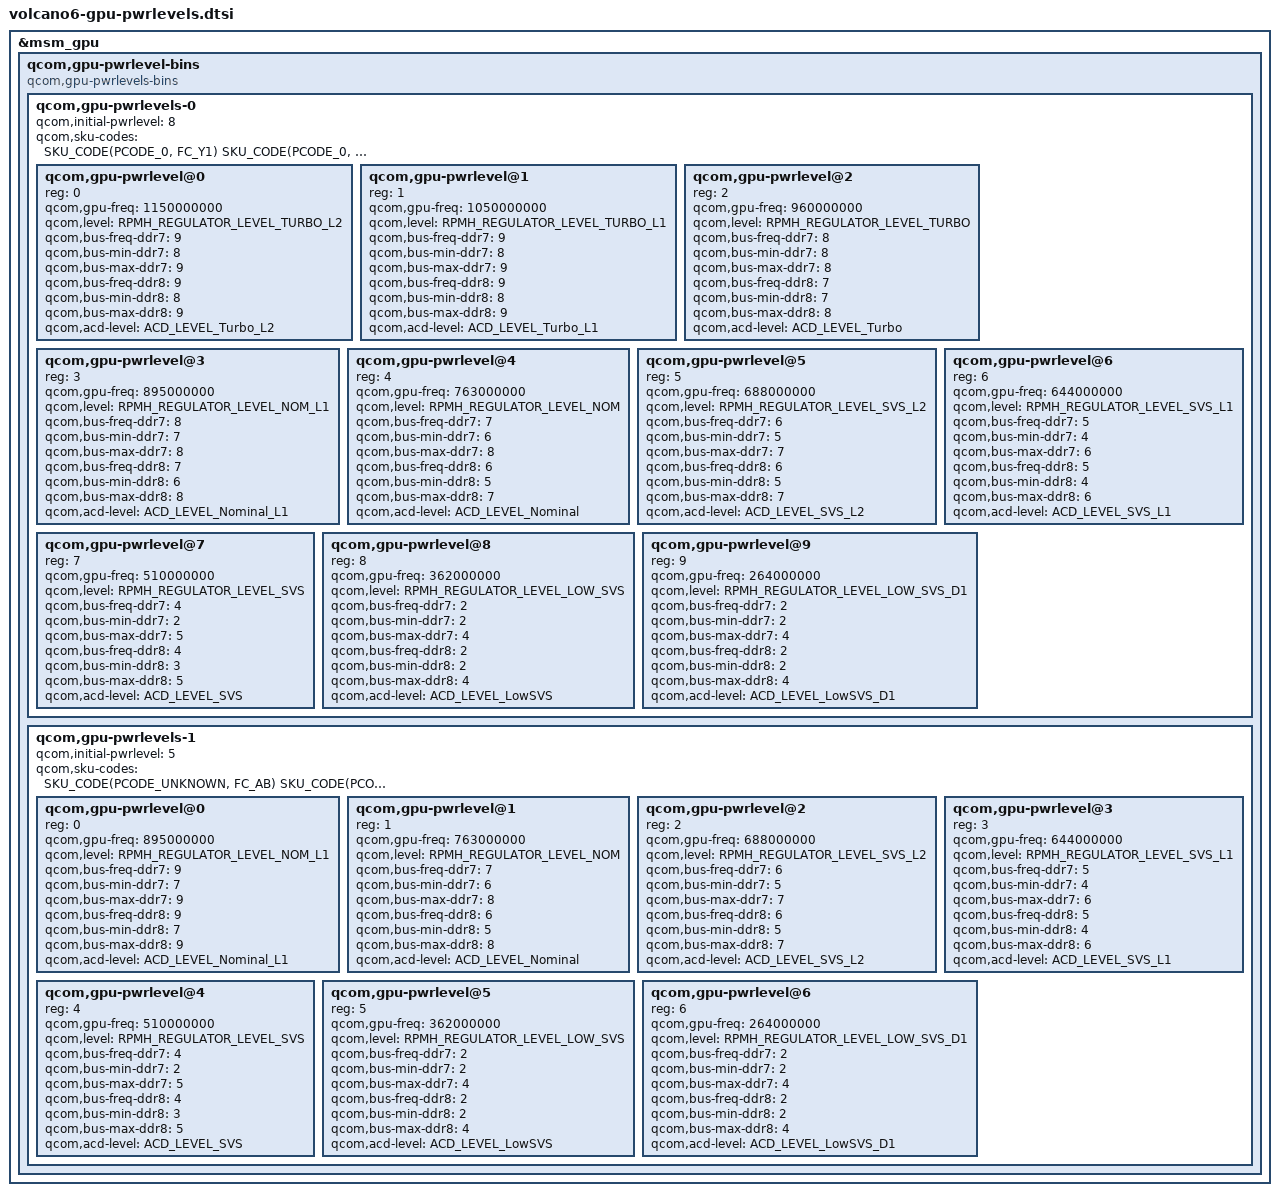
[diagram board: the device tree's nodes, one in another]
&msm_gpu {
	/* Power level bins */
	qcom,gpu-pwrlevel-bins {
		compatible = "qcom,gpu-pwrlevels-bins";

		#address-cells = <1>;
		#size-cells = <0>;

		qcom,gpu-pwrlevels-0 {

			#address-cells = <1>;
			#size-cells = <0>;

			qcom,initial-pwrlevel = <8>;

			qcom,sku-codes = <SKU_CODE(PCODE_0, FC_Y1)
				SKU_CODE(PCODE_0, FC_Y0)>;

			qcom,gpu-pwrlevel@0 {
				reg = <0>;
				qcom,gpu-freq = <1150000000>;
				qcom,level = <RPMH_REGULATOR_LEVEL_TURBO_L2>;

				qcom,bus-freq-ddr7 = <9>;
				qcom,bus-min-ddr7 = <8>;
				qcom,bus-max-ddr7 = <9>;

				qcom,bus-freq-ddr8 = <9>;
				qcom,bus-min-ddr8 = <8>;
				qcom,bus-max-ddr8 = <9>;

				qcom,acd-level = <ACD_LEVEL_Turbo_L2>;
			};

			qcom,gpu-pwrlevel@1 {
				reg = <1>;
				qcom,gpu-freq = <1050000000>;
				qcom,level = <RPMH_REGULATOR_LEVEL_TURBO_L1>;

				qcom,bus-freq-ddr7 = <9>;
				qcom,bus-min-ddr7 = <8>;
				qcom,bus-max-ddr7 = <9>;

				qcom,bus-freq-ddr8 = <9>;
				qcom,bus-min-ddr8 = <8>;
				qcom,bus-max-ddr8 = <9>;

				qcom,acd-level = <ACD_LEVEL_Turbo_L1>;
			};

			qcom,gpu-pwrlevel@2 {
				reg = <2>;
				qcom,gpu-freq = <960000000>;
				qcom,level = <RPMH_REGULATOR_LEVEL_TURBO>;

				qcom,bus-freq-ddr7 = <8>;
				qcom,bus-min-ddr7 = <8>;
				qcom,bus-max-ddr7 = <8>;

				qcom,bus-freq-ddr8 = <7>;
				qcom,bus-min-ddr8 = <7>;
				qcom,bus-max-ddr8 = <8>;

				qcom,acd-level = <ACD_LEVEL_Turbo>;
			};

			qcom,gpu-pwrlevel@3 {
				reg = <3>;
				qcom,gpu-freq = <895000000>;
				qcom,level = <RPMH_REGULATOR_LEVEL_NOM_L1>;

				qcom,bus-freq-ddr7 = <8>;
				qcom,bus-min-ddr7 = <7>;
				qcom,bus-max-ddr7 = <8>;

				qcom,bus-freq-ddr8 = <7>;
				qcom,bus-min-ddr8 = <6>;
				qcom,bus-max-ddr8 = <8>;

				qcom,acd-level = <ACD_LEVEL_Nominal_L1>;
			};

			qcom,gpu-pwrlevel@4 {
				reg = <4>;
				qcom,gpu-freq = <763000000>;
				qcom,level = <RPMH_REGULATOR_LEVEL_NOM>;

				qcom,bus-freq-ddr7 = <7>;
				qcom,bus-min-ddr7 = <6>;
				qcom,bus-max-ddr7 = <8>;

				qcom,bus-freq-ddr8 = <6>;
				qcom,bus-min-ddr8 = <5>;
				qcom,bus-max-ddr8 = <7>;

				qcom,acd-level = <ACD_LEVEL_Nominal>;
			};

			qcom,gpu-pwrlevel@5 {
				reg = <5>;
				qcom,gpu-freq = <688000000>;
				qcom,level = <RPMH_REGULATOR_LEVEL_SVS_L2>;

				qcom,bus-freq-ddr7 = <6>;
				qcom,bus-min-ddr7 = <5>;
				qcom,bus-max-ddr7 = <7>;

				qcom,bus-freq-ddr8 = <6>;
				qcom,bus-min-ddr8 = <5>;
				qcom,bus-max-ddr8 = <7>;

				qcom,acd-level = <ACD_LEVEL_SVS_L2>;
			};

			qcom,gpu-pwrlevel@6 {
				reg = <6>;
				qcom,gpu-freq = <644000000>;
				qcom,level = <RPMH_REGULATOR_LEVEL_SVS_L1>;

				qcom,bus-freq-ddr7 = <5>;
				qcom,bus-min-ddr7 = <4>;
				qcom,bus-max-ddr7 = <6>;

				qcom,bus-freq-ddr8 = <5>;
				qcom,bus-min-ddr8 = <4>;
				qcom,bus-max-ddr8 = <6>;

				qcom,acd-level = <ACD_LEVEL_SVS_L1>;
			};

			qcom,gpu-pwrlevel@7 {
				reg = <7>;
				qcom,gpu-freq = <510000000>;
				qcom,level = <RPMH_REGULATOR_LEVEL_SVS>;

				qcom,bus-freq-ddr7 = <4>;
				qcom,bus-min-ddr7 = <2>;
				qcom,bus-max-ddr7 = <5>;

				qcom,bus-freq-ddr8 = <4>;
				qcom,bus-min-ddr8 = <3>;
				qcom,bus-max-ddr8 = <5>;

				qcom,acd-level = <ACD_LEVEL_SVS>;
			};

			qcom,gpu-pwrlevel@8 {
				reg = <8>;
				qcom,gpu-freq = <362000000>;
				qcom,level = <RPMH_REGULATOR_LEVEL_LOW_SVS>;

				qcom,bus-freq-ddr7 = <2>;
				qcom,bus-min-ddr7 = <2>;
				qcom,bus-max-ddr7 = <4>;

				qcom,bus-freq-ddr8 = <2>;
				qcom,bus-min-ddr8 = <2>;
				qcom,bus-max-ddr8 = <4>;

				qcom,acd-level = <ACD_LEVEL_LowSVS>;
			};

			qcom,gpu-pwrlevel@9 {
				reg = <9>;
				qcom,gpu-freq = <264000000>;
				qcom,level = <RPMH_REGULATOR_LEVEL_LOW_SVS_D1>;

				qcom,bus-freq-ddr7 = <2>;
				qcom,bus-min-ddr7 = <2>;
				qcom,bus-max-ddr7 = <4>;

				qcom,bus-freq-ddr8 = <2>;
				qcom,bus-min-ddr8 = <2>;
				qcom,bus-max-ddr8 = <4>;

				qcom,acd-level = <ACD_LEVEL_LowSVS_D1>;
			};

		};

		qcom,gpu-pwrlevels-1 {

			#address-cells = <1>;
			#size-cells = <0>;

			qcom,initial-pwrlevel = <5>;

			qcom,sku-codes = <SKU_CODE(PCODE_UNKNOWN, FC_AB)
				SKU_CODE(PCODE_UNKNOWN, FC_UNKNOWN)>;

			qcom,gpu-pwrlevel@0 {
				reg = <0>;
				qcom,gpu-freq = <895000000>;
				qcom,level = <RPMH_REGULATOR_LEVEL_NOM_L1>;

				qcom,bus-freq-ddr7 = <9>;
				qcom,bus-min-ddr7 = <7>;
				qcom,bus-max-ddr7 = <9>;

				qcom,bus-freq-ddr8 = <9>;
				qcom,bus-min-ddr8 = <7>;
				qcom,bus-max-ddr8 = <9>;

				qcom,acd-level = <ACD_LEVEL_Nominal_L1>;
			};

			qcom,gpu-pwrlevel@1 {
				reg = <1>;
				qcom,gpu-freq = <763000000>;
				qcom,level = <RPMH_REGULATOR_LEVEL_NOM>;

				qcom,bus-freq-ddr7 = <7>;
				qcom,bus-min-ddr7 = <6>;
				qcom,bus-max-ddr7 = <8>;

				qcom,bus-freq-ddr8 = <6>;
				qcom,bus-min-ddr8 = <5>;
				qcom,bus-max-ddr8 = <8>;

				qcom,acd-level = <ACD_LEVEL_Nominal>;
			};

			qcom,gpu-pwrlevel@2 {
				reg = <2>;
				qcom,gpu-freq = <688000000>;
				qcom,level = <RPMH_REGULATOR_LEVEL_SVS_L2>;

				qcom,bus-freq-ddr7 = <6>;
				qcom,bus-min-ddr7 = <5>;
				qcom,bus-max-ddr7 = <7>;

				qcom,bus-freq-ddr8 = <6>;
				qcom,bus-min-ddr8 = <5>;
				qcom,bus-max-ddr8 = <7>;

				qcom,acd-level = <ACD_LEVEL_SVS_L2>;
			};

			qcom,gpu-pwrlevel@3 {
				reg = <3>;
				qcom,gpu-freq = <644000000>;
				qcom,level = <RPMH_REGULATOR_LEVEL_SVS_L1>;

				qcom,bus-freq-ddr7 = <5>;
				qcom,bus-min-ddr7 = <4>;
				qcom,bus-max-ddr7 = <6>;

				qcom,bus-freq-ddr8 = <5>;
				qcom,bus-min-ddr8 = <4>;
				qcom,bus-max-ddr8 = <6>;

				qcom,acd-level = <ACD_LEVEL_SVS_L1>;
			};

			qcom,gpu-pwrlevel@4 {
				reg = <4>;
				qcom,gpu-freq = <510000000>;
				qcom,level = <RPMH_REGULATOR_LEVEL_SVS>;

				qcom,bus-freq-ddr7 = <4>;
				qcom,bus-min-ddr7 = <2>;
				qcom,bus-max-ddr7 = <5>;

				qcom,bus-freq-ddr8 = <4>;
				qcom,bus-min-ddr8 = <3>;
				qcom,bus-max-ddr8 = <5>;

				qcom,acd-level = <ACD_LEVEL_SVS>;
			};

			qcom,gpu-pwrlevel@5 {
				reg = <5>;
				qcom,gpu-freq = <362000000>;
				qcom,level = <RPMH_REGULATOR_LEVEL_LOW_SVS>;

				qcom,bus-freq-ddr7 = <2>;
				qcom,bus-min-ddr7 = <2>;
				qcom,bus-max-ddr7 = <4>;

				qcom,bus-freq-ddr8 = <2>;
				qcom,bus-min-ddr8 = <2>;
				qcom,bus-max-ddr8 = <4>;

				qcom,acd-level = <ACD_LEVEL_LowSVS>;
			};

			qcom,gpu-pwrlevel@6 {
				reg = <6>;
				qcom,gpu-freq = <264000000>;
				qcom,level = <RPMH_REGULATOR_LEVEL_LOW_SVS_D1>;

				qcom,bus-freq-ddr7 = <2>;
				qcom,bus-min-ddr7 = <2>;
				qcom,bus-max-ddr7 = <4>;

				qcom,bus-freq-ddr8 = <2>;
				qcom,bus-min-ddr8 = <2>;
				qcom,bus-max-ddr8 = <4>;

				qcom,acd-level = <ACD_LEVEL_LowSVS_D1>;
			};

		};
	};
};
